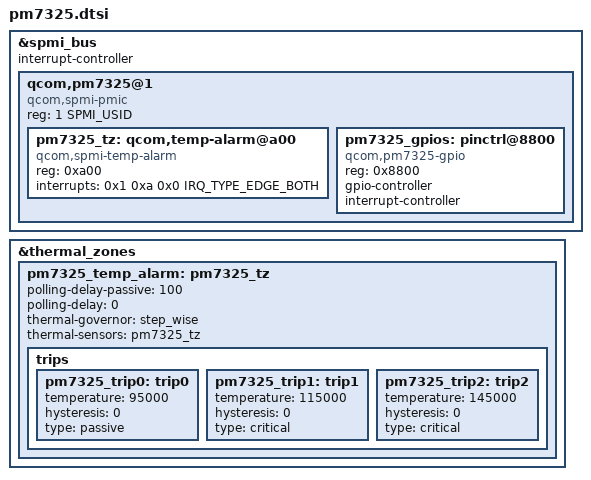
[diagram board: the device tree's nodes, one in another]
#include <dt-bindings/interrupt-controller/irq.h>
#include <dt-bindings/spmi/spmi.h>

&spmi_bus {
	#address-cells = <2>;
	#size-cells = <0>;
	interrupt-controller;
	#interrupt-cells = <4>;

	qcom,pm7325@1 {
		compatible = "qcom,spmi-pmic";
		reg = <1 SPMI_USID>;
		#address-cells = <1>;
		#size-cells = <0>;

		pm7325_tz: qcom,temp-alarm@a00 {
			compatible = "qcom,spmi-temp-alarm";
			reg = <0xa00>;
			interrupts = <0x1 0xa 0x0 IRQ_TYPE_EDGE_BOTH>;
			#thermal-sensor-cells = <0>;
		};

		pm7325_gpios: pinctrl@8800 {
			compatible = "qcom,pm7325-gpio";
			reg = <0x8800>;
			gpio-controller;
			#gpio-cells = <2>;
			interrupt-controller;
			#interrupt-cells = <2>;
		};
	};
};

&thermal_zones {
	pm7325_temp_alarm: pm7325_tz {
		polling-delay-passive = <100>;
		polling-delay = <0>;
		thermal-governor = "step_wise";
		thermal-sensors = <&pm7325_tz>;

		trips {
			pm7325_trip0: trip0 {
				temperature = <95000>;
				hysteresis = <0>;
				type = "passive";
			};

			pm7325_trip1: trip1 {
				temperature = <115000>;
				hysteresis = <0>;
				type = "critical";
			};

			pm7325_trip2: trip2 {
				temperature = <145000>;
				hysteresis = <0>;
				type = "critical";
			};
		};
	};
};
